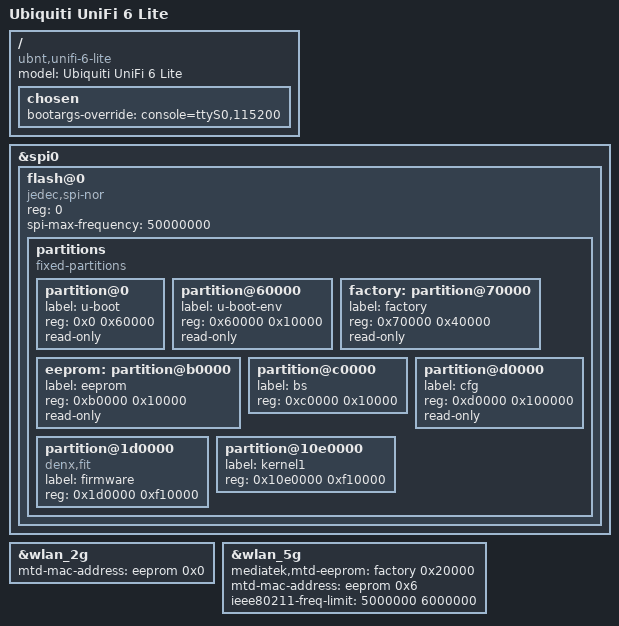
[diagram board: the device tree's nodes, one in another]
// SPDX-License-Identifier: GPL-2.0-or-later OR MIT

#include "mt7621_ubnt_unifi.dtsi"

/ {
	compatible = "ubnt,unifi-6-lite", "mediatek,mt7621-soc";
	model = "Ubiquiti UniFi 6 Lite";

	chosen {
		bootargs-override = "console=ttyS0,115200";
	};
};

&spi0 {
	status = "okay";

	flash@0 {
		compatible = "jedec,spi-nor";
		reg = <0>;
		spi-max-frequency = <50000000>;

		partitions {
			compatible = "fixed-partitions";
			#address-cells = <1>;
			#size-cells = <1>;

			partition@0 {
				label = "u-boot";
				reg = <0x0 0x60000>;
				read-only;
			};

			partition@60000 {
				label = "u-boot-env";
				reg = <0x60000 0x10000>;
				read-only;
			};

			factory: partition@70000 {
				label = "factory";
				reg = <0x70000 0x40000>;
				read-only;
			};

			eeprom: partition@b0000 {
				label = "eeprom";
				reg = <0xb0000 0x10000>;
				read-only;
			};

			partition@c0000 {
				label = "bs";
				reg = <0xc0000 0x10000>;
			};

			partition@d0000 {
				label = "cfg";
				reg = <0xd0000 0x100000>;
				read-only;
			};

			partition@1d0000 {
				compatible = "denx,fit";
				label = "firmware";
				reg = <0x1d0000 0xf10000>;
			};

			partition@10e0000 {
				label = "kernel1";
				reg = <0x10e0000 0xf10000>;
			};
		};
	};
};

&wlan_2g {
	mtd-mac-address = <&eeprom 0x0>;
};

&wlan_5g {
	mediatek,mtd-eeprom = <&factory 0x20000>;
	mtd-mac-address = <&eeprom 0x6>;
	ieee80211-freq-limit = <5000000 6000000>;
};
